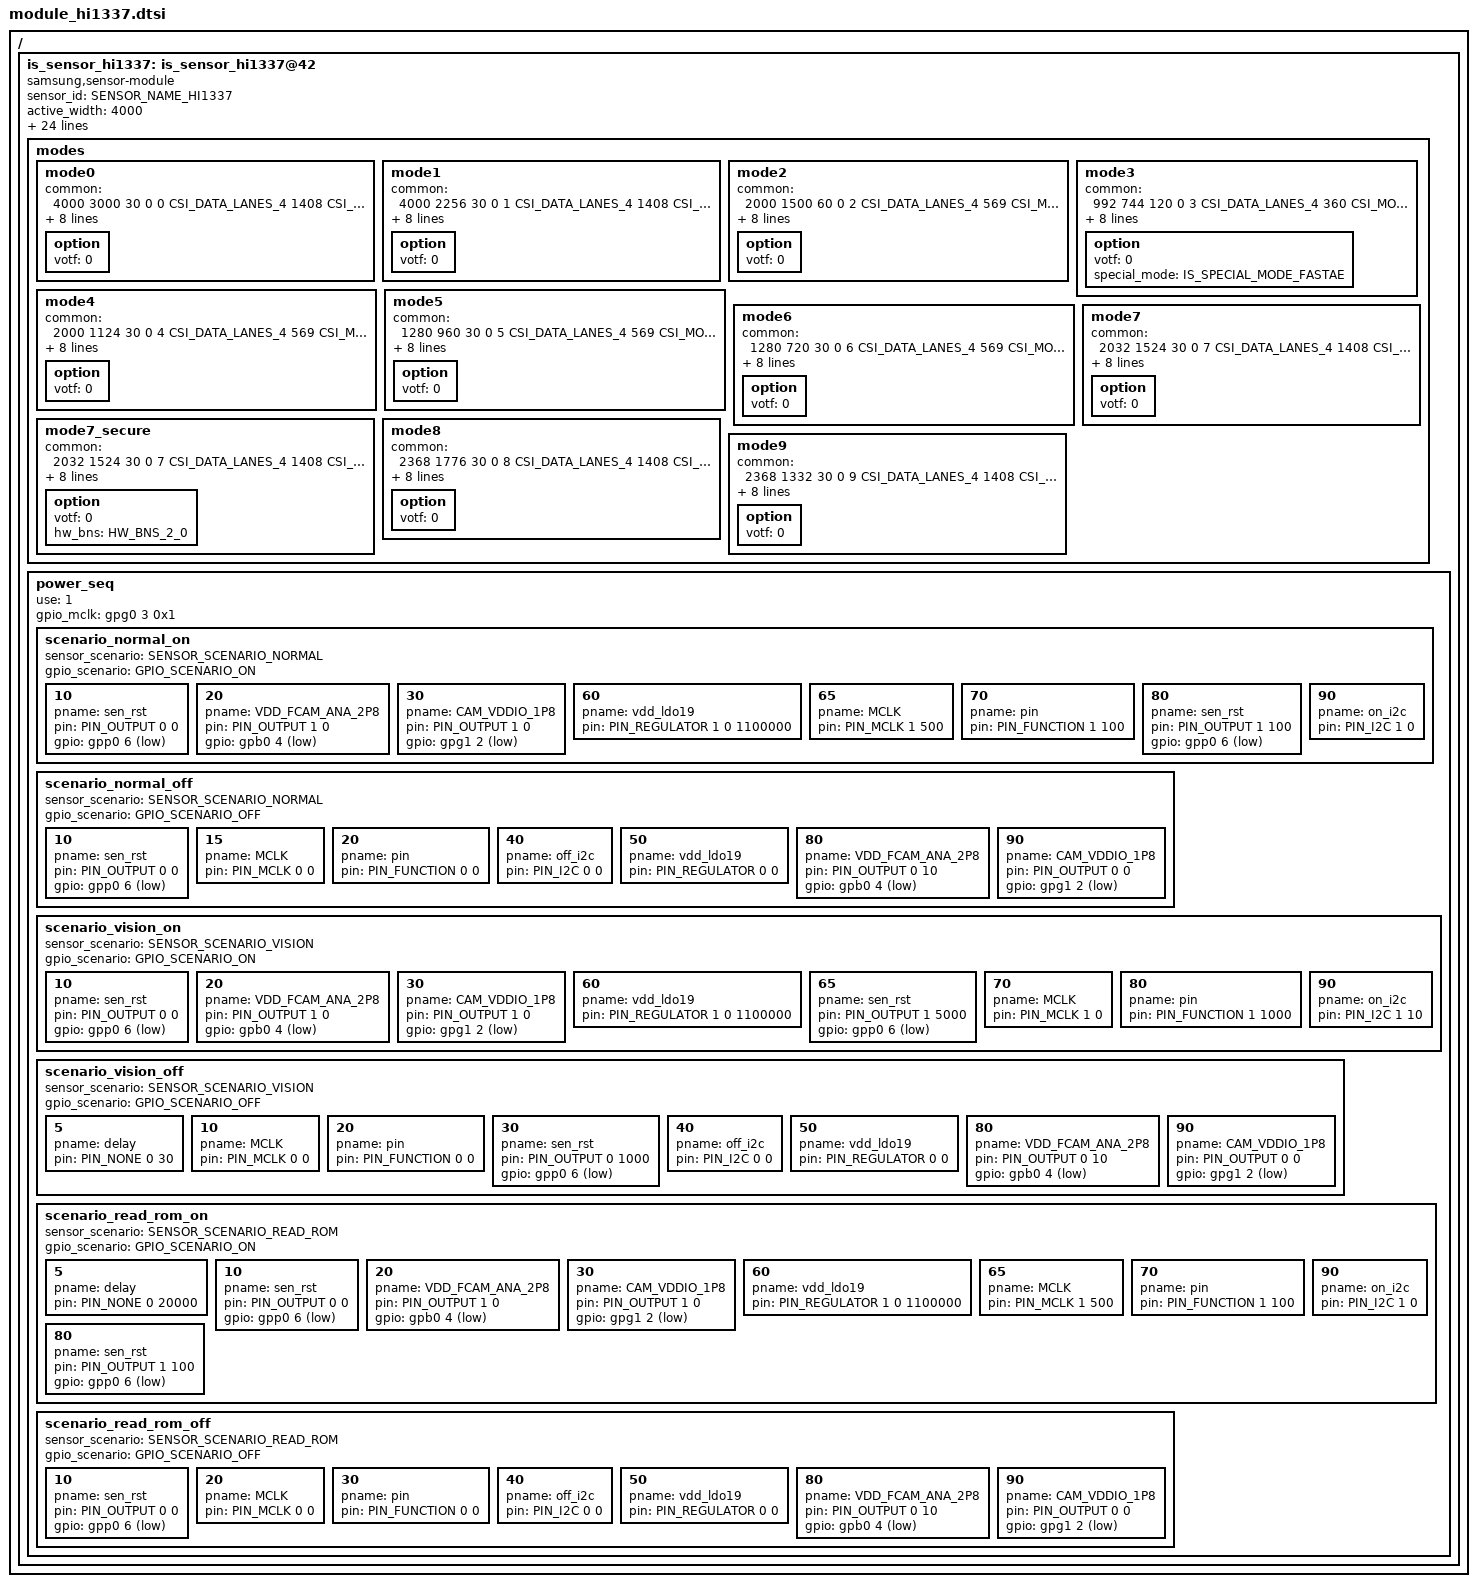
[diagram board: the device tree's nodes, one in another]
/*
 * SAMSUNG EXYNOSxxxx board camera device tree source
 *
 * Copyright (c) 2024 Samsung Electronics Co., Ltd.
 *		http://www.samsung.com
 *
 * This program is free software; you can redistribute it and/or modify
 * it under the terms of the GNU General Public License version 2 as
 * published by the Free Software Foundation.
 */

#include <dt-bindings/camera/exynos_is_dt.h>

/ {
	fragment@camera {
		target-path = "/";
		__overlay__ {
			is_sensor_hi1337: is_sensor_hi1337@42 {
				compatible = "samsung,sensor-module";

				/* common */
				sensor_id = <SENSOR_NAME_HI1337>;
				active_width = <4000>;
				active_height = <3000>;
				margin_left = <0>;
				margin_right = <0>;
				margin_top = <0>;
				margin_bottom = <0>;
				max_framerate = <120>;
				bitwidth = <10>;
				use_retention_mode = <SENSOR_RETENTION_UNSUPPORTED>;
				sensor_maker = "HYNIX";
				sensor_name = "HI1337";
				setfile_name = "setfile_hi1337.bin";
				pinning_setfile;
				//preload_setfile;

				status = "okay";

				/* board */
				pinctrl-names = "pin0", "pin1", "release";
				pinctrl-0 = <&sensor_mclk2_out>;
				pinctrl-1 = <&sensor_mclk2_fn>;
				pinctrl-2 = <>;

				position = <1>; /* Rear:0. Front:1, Tele:2 */
				id = <1>; /* is_sensor id */
				mclk_ch = <2>;
				mclk_freq = <19200>;
				sensor_i2c_ch = <4>; /* SENSOR_CONTROL_I2C1 */

				/* vendor */
				rom_id = <1>;
				rom_cal_index = <0>;
				rom_type = <3>; /* ROM_TYPE_OTPROM */
#if 0
				vc_extra {
					/* ex) statX = <stat_type, sensor_mode, max_width, max_height, max_element> */
					/* VC_BUF_DATA_TYPE_SENSOR_STAT1 */
					stat0 = </*VC_STAT_TYPE_TAIL_FOR_3HDR_IMX_2_STAT0*/ 602    /*VC_SENSOR_MODE_3HDR_IMX_2*/ 602 4080 2 1>;
					/* VC_BUF_DATA_TYPE_GENERAL_STAT1 */
					stat1 = </* not available */>;
					/* VC_BUF_DATA_TYPE_SENSOR_STAT2 */
					stat2 = </*VC_STAT_TYPE_TAIL_FOR_3HDR_IMX_2_STAT1*/ 603    /*VC_SENSOR_MODE_3HDR_IMX_2*/ 602 4080 3 1>;
					/* VC_BUF_DATA_TYPE_GENERAL_STAT2 */
					stat3 = </* not available */>;
				};
#endif

				/* sensor modes */
				modes {
						/* common = <width, height, fps, settle, mode, lane, speed, interleave, lrte, pd_mode> */
						/* vcX = <map, hwformat, width, height, hwformat, type, width, height> */

						/* 0 : 4000x3000_30FPS */
						mode0 {
								common = <4000 3000 30 0 0 CSI_DATA_LANES_4 1408 CSI_MODE_VC_ONLY LRTE_DISABLE PD_NONE EX_NONE>;
								vc0 = </* in */ 0 HW_FORMAT_RAW10 DATA_IMG 4000 3000 /* out */ HW_FORMAT_RAW10 VC_NOTHING 4000 3000>;
								vc1 = </* in */ 1 HW_FORMAT_UNKNOWN DATA_NONE 0 0 /* out */ HW_FORMAT_UNKNOWN VC_NOTHING 0 0>;
								vc2 = </* in */ 2 HW_FORMAT_UNKNOWN DATA_NONE 0 0 /* out */ HW_FORMAT_UNKNOWN VC_NOTHING 0 0>;
								vc3 = </* in */ 3 HW_FORMAT_UNKNOWN DATA_NONE 0 0 /* out */ HW_FORMAT_UNKNOWN VC_NOTHING 0 0>;
								option { votf = <0>; };
						};

						/* 1 : 4000x2256_30FPS */
						mode1 {
								common = <4000 2256 30 0 1 CSI_DATA_LANES_4 1408 CSI_MODE_VC_ONLY LRTE_DISABLE PD_NONE EX_NONE>;
								vc0 = </* in */ 0 HW_FORMAT_RAW10 DATA_IMG 4000 2256     /* out */ HW_FORMAT_RAW10 VC_NOTHING 4000 2256>;
								vc1 = </* in */ 1 HW_FORMAT_UNKNOWN DATA_NONE 0 0 /* out */ HW_FORMAT_UNKNOWN VC_NOTHING 0 0>;
								vc2 = </* in */ 2 HW_FORMAT_UNKNOWN DATA_NONE 0 0 /* out */ HW_FORMAT_UNKNOWN VC_NOTHING 0 0>;
								vc3 = </* in */ 3 HW_FORMAT_UNKNOWN DATA_NONE 0 0 /* out */ HW_FORMAT_UNKNOWN VC_NOTHING 0 0>;
								option { votf = <0>; };
						};

						/* 2 : 2000x1500_60fps */
						mode2 {
								common = <2000 1500 60 0 2 CSI_DATA_LANES_4 569 CSI_MODE_VC_ONLY LRTE_DISABLE PD_NONE EX_NONE>;
								vc0 = </* in */ 0 HW_FORMAT_RAW10 DATA_IMG 2000 1500 /* out */ HW_FORMAT_RAW10 VC_NOTHING 2000 1500>;
								vc1 = </* in */ 1 HW_FORMAT_UNKNOWN DATA_NONE 0 0 /* out */ HW_FORMAT_UNKNOWN VC_NOTHING 0 0>;
								vc2 = </* in */ 2 HW_FORMAT_UNKNOWN DATA_NONE 0 0 /* out */ HW_FORMAT_UNKNOWN VC_NOTHING 0 0>;
								vc3 = </* in */ 3 HW_FORMAT_UNKNOWN DATA_NONE 0 0 /* out */ HW_FORMAT_UNKNOWN VC_NOTHING 0 0>;
								option { votf = <0>; };
						};

						/* 3 : 992x744_120fps */
						mode3 {
								common = <992 744 120 0 3 CSI_DATA_LANES_4 360 CSI_MODE_VC_ONLY LRTE_DISABLE PD_NONE EX_NONE>;
								vc0 = </* in */ 0 HW_FORMAT_RAW10 DATA_IMG 992 744     /* out */ HW_FORMAT_RAW10 VC_NOTHING 992 744>;
								vc1 = </* in */ 1 HW_FORMAT_UNKNOWN DATA_NONE 0 0 /* out */ HW_FORMAT_UNKNOWN VC_NOTHING 0 0>;
								vc2 = </* in */ 2 HW_FORMAT_UNKNOWN DATA_NONE 0 0 /* out */ HW_FORMAT_UNKNOWN VC_NOTHING 0 0>;
								vc3 = </* in */ 3 HW_FORMAT_UNKNOWN DATA_NONE 0 0 /* out */ HW_FORMAT_UNKNOWN VC_NOTHING 0 0>;
								option { votf = <0>; special_mode = <IS_SPECIAL_MODE_FASTAE>; };
						};

						/* 4 : 2000x1124_30fps */
						mode4 {
								common = <2000 1124 30 0 4 CSI_DATA_LANES_4 569 CSI_MODE_VC_ONLY LRTE_DISABLE PD_NONE EX_NONE>;
								vc0 = </* in */ 0 HW_FORMAT_RAW10 DATA_IMG 2000 1124 /* out */ HW_FORMAT_RAW10 VC_NOTHING 2000 1124>;
								vc1 = </* in */ 1 HW_FORMAT_UNKNOWN DATA_NONE 0 0 /* out */ HW_FORMAT_UNKNOWN VC_NOTHING 0 0>;
								vc2 = </* in */ 2 HW_FORMAT_UNKNOWN DATA_NONE 0 0 /* out */ HW_FORMAT_UNKNOWN VC_NOTHING 0 0>;
								vc3 = </* in */ 3 HW_FORMAT_UNKNOWN DATA_NONE 0 0 /* out */ HW_FORMAT_UNKNOWN VC_NOTHING 0 0>;
								option { votf = <0>; };
						};

						/* 5 : 1280x960_30fps */
						mode5 {
								common = <1280 960 30 0 5 CSI_DATA_LANES_4 569 CSI_MODE_VC_ONLY LRTE_DISABLE PD_NONE EX_NONE>;
								vc0 = </* in */ 0 HW_FORMAT_RAW10 DATA_IMG 1280 960     /* out */ HW_FORMAT_RAW10 VC_NOTHING 1280 960>;
								vc1 = </* in */ 1 HW_FORMAT_UNKNOWN DATA_NONE 0 0 /* out */ HW_FORMAT_UNKNOWN VC_NOTHING 0 0>;
								vc2 = </* in */ 2 HW_FORMAT_UNKNOWN DATA_NONE 0 0 /* out */ HW_FORMAT_UNKNOWN VC_NOTHING 0 0>;
								vc3 = </* in */ 3 HW_FORMAT_UNKNOWN DATA_NONE 0 0 /* out */ HW_FORMAT_UNKNOWN VC_NOTHING 0 0>;
								option { votf = <0>; };
						};

						/* 6 : 1280x720_30fps */
						mode6 {
								common = <1280 720 30 0 6 CSI_DATA_LANES_4 569 CSI_MODE_VC_ONLY LRTE_DISABLE PD_NONE EX_NONE>;
								vc0 = </* in */ 0 HW_FORMAT_RAW10 DATA_IMG 1280 720     /* out */ HW_FORMAT_RAW10 VC_NOTHING 1280 720>;
								vc1 = </* in */ 1 HW_FORMAT_UNKNOWN DATA_NONE 0 0 /* out */ HW_FORMAT_UNKNOWN VC_NOTHING 0 0>;
								vc2 = </* in */ 2 HW_FORMAT_UNKNOWN DATA_NONE 0 0 /* out */ HW_FORMAT_UNKNOWN VC_NOTHING 0 0>;
								vc3 = </* in */ 3 HW_FORMAT_UNKNOWN DATA_NONE 0 0 /* out */ HW_FORMAT_UNKNOWN VC_NOTHING 0 0>;
								option { votf = <0>; };
						};

						/* 7 : 2032x1524_30fps */
						mode7 {
								common = <2032 1524 30 0 7 CSI_DATA_LANES_4 1408 CSI_MODE_VC_ONLY LRTE_DISABLE PD_NONE EX_NONE>;
								vc0 = </* in */ 0 HW_FORMAT_RAW10 DATA_IMG 2032 1524     /* out */ HW_FORMAT_RAW10 VC_NOTHING 2032 1524>;
								vc1 = </* in */ 1 HW_FORMAT_UNKNOWN DATA_NONE 0 0 /* out */ HW_FORMAT_UNKNOWN VC_NOTHING 0 0>;
								vc2 = </* in */ 2 HW_FORMAT_UNKNOWN DATA_NONE 0 0 /* out */ HW_FORMAT_UNKNOWN VC_NOTHING 0 0>;
								vc3 = </* in */ 3 HW_FORMAT_UNKNOWN DATA_NONE 0 0 /* out */ HW_FORMAT_UNKNOWN VC_NOTHING 0 0>;
								option { votf = <0>; };
						};

						mode7_secure {
								common = <2032 1524 30 0 7 CSI_DATA_LANES_4 1408 CSI_MODE_VC_ONLY LRTE_DISABLE PD_NONE EX_PDAF_OFF>;
								vc0 = </* in */ 0 HW_FORMAT_RAW10 DATA_IMG 2032 1524 /* out */ HW_FORMAT_RAW10 VC_NOTHING 1016 762>;
								vc1 = </* in */ 1 HW_FORMAT_UNKNOWN DATA_NONE 0 0 /* out */ HW_FORMAT_UNKNOWN VC_NOTHING 0 0>;
								vc2 = </* in */ 2 HW_FORMAT_UNKNOWN DATA_NONE 0 0 /* out */ HW_FORMAT_UNKNOWN VC_NOTHING 0 0>;
								vc3 = </* in */ 3 HW_FORMAT_UNKNOWN DATA_NONE 0 0 /* out */ HW_FORMAT_UNKNOWN VC_NOTHING 0 0>;
								option { votf = <0>; hw_bns = <HW_BNS_2_0>; };
						};

						mode8 {
								common = <2368 1776 30 0 8 CSI_DATA_LANES_4 1408 CSI_MODE_VC_ONLY LRTE_DISABLE PD_NONE EX_NONE>;
								vc0 = </* in */ 0 HW_FORMAT_RAW10 DATA_IMG 2368 1776     /* out */ HW_FORMAT_RAW10 VC_NOTHING 2368 1776>;
								vc1 = </* in */ 1 HW_FORMAT_UNKNOWN DATA_NONE 0 0 /* out */ HW_FORMAT_UNKNOWN VC_NOTHING 0 0>;
								vc2 = </* in */ 2 HW_FORMAT_UNKNOWN DATA_NONE 0 0 /* out */ HW_FORMAT_UNKNOWN VC_NOTHING 0 0>;
								vc3 = </* in */ 3 HW_FORMAT_UNKNOWN DATA_NONE 0 0 /* out */ HW_FORMAT_UNKNOWN VC_NOTHING 0 0>;
								option { votf = <0>; };
						};

						mode9 {
								common = <2368 1332 30 0 9 CSI_DATA_LANES_4 1408 CSI_MODE_VC_ONLY LRTE_DISABLE PD_NONE EX_NONE>;
								vc0 = </* in */ 0 HW_FORMAT_RAW10 DATA_IMG 2368 1332    /* out */ HW_FORMAT_RAW10 VC_NOTHING 2368 1332>;
								vc1 = </* in */ 1 HW_FORMAT_UNKNOWN DATA_NONE 0 0 /* out */ HW_FORMAT_UNKNOWN VC_NOTHING 0 0>;
								vc2 = </* in */ 2 HW_FORMAT_UNKNOWN DATA_NONE 0 0 /* out */ HW_FORMAT_UNKNOWN VC_NOTHING 0 0>;
								vc3 = </* in */ 3 HW_FORMAT_UNKNOWN DATA_NONE 0 0 /* out */ HW_FORMAT_UNKNOWN VC_NOTHING 0 0>;
								option { votf = <0>; };
						};

				};

				power_seq {
					use = <1>;
					gpio_mclk = <&gpg0 3 0x1>;
					scenario_normal_on {
						sensor_scenario = <SENSOR_SCENARIO_NORMAL>;
						gpio_scenario = <GPIO_SCENARIO_ON>;

						/* A start node number should be over the 10 for reserved number 0~9. */
						/* pname = "name"; pin = <act value delay voltage>; gpio = <gpx# # 0x1>; */
						10 { pname = "sen_rst"; pin = <PIN_OUTPUT 0 0>; gpio = <&gpp0 6 0x1>; };
						20 { pname = "VDD_FCAM_ANA_2P8"; pin = <PIN_OUTPUT 1 0>; gpio = <&gpb0 4 0x1>; };
						30 { pname = "CAM_VDDIO_1P8"; pin = <PIN_OUTPUT 1 0>; gpio = <&gpg1 2 0x1>; };
						60 { pname = "vdd_ldo19"; pin = <PIN_REGULATOR 1 0 1100000>; };
						65 { pname = "MCLK"; pin = <PIN_MCLK 1 500>; };
						70 { pname = "pin"; pin = <PIN_FUNCTION 1 100>; };
						80 { pname = "sen_rst"; pin = <PIN_OUTPUT 1 100>; gpio = <&gpp0 6 0x1>; };
						90 { pname = "on_i2c"; pin = <PIN_I2C 1 0>; };
					};

					scenario_normal_off {
						sensor_scenario = <SENSOR_SCENARIO_NORMAL>;
						gpio_scenario = <GPIO_SCENARIO_OFF>;

						/* A start node number should be over the 10 for reserved number 0~9. */
						/* pname = "name"; pin = <act value delay voltage>; gpio = <gpx# # 0x1>; */
						10 { pname = "sen_rst"; pin = <PIN_OUTPUT 0 0>; gpio = <&gpp0 6 0x1>; };
						15 { pname = "MCLK"; pin = <PIN_MCLK 0 0>; };
						20 { pname = "pin"; pin = <PIN_FUNCTION 0 0>; };
						40 { pname = "off_i2c"; pin = <PIN_I2C 0 0>; };
						50 { pname = "vdd_ldo19"; pin = <PIN_REGULATOR 0 0>; };
						80 { pname = "VDD_FCAM_ANA_2P8"; pin = <PIN_OUTPUT 0 10>; gpio = <&gpb0 4 0x1>; };
						90 { pname = "CAM_VDDIO_1P8"; pin = <PIN_OUTPUT 0 0>; gpio = <&gpg1 2 0x1>; };
					};

					scenario_vision_on {
						sensor_scenario = <SENSOR_SCENARIO_VISION>;
						gpio_scenario = <GPIO_SCENARIO_ON>;

						/* A start node number should be over the 10 for reserved number 0~9. */
						/* pname = "name"; pin = <act value delay voltage>; gpio = <gpx# # 0x1>; */
						10 { pname = "sen_rst"; pin = <PIN_OUTPUT 0 0>; gpio = <&gpp0 6 0x1>; };
						20 { pname = "VDD_FCAM_ANA_2P8"; pin = <PIN_OUTPUT 1 0>; gpio = <&gpb0 4 0x1>; };
						30 { pname = "CAM_VDDIO_1P8"; pin = <PIN_OUTPUT 1 0>; gpio = <&gpg1 2 0x1>; };
						60 { pname = "vdd_ldo19"; pin = <PIN_REGULATOR 1 0 1100000>; };
						65 { pname = "sen_rst"; pin = <PIN_OUTPUT 1 5000>; gpio = <&gpp0 6 0x1>; };
						70 { pname = "MCLK"; pin = <PIN_MCLK 1 0>; };
						80 { pname = "pin"; pin = <PIN_FUNCTION 1 1000>; };
						90 { pname = "on_i2c"; pin = <PIN_I2C 1 10>; };
					};

					scenario_vision_off {
						sensor_scenario = <SENSOR_SCENARIO_VISION>;
						gpio_scenario = <GPIO_SCENARIO_OFF>;

						/* A start node number should be over the 10 for reserved number 0~9. */
						/* pname = "name"; pin = <act value delay voltage>; gpio = <gpx# # 0x1>; */
						5 { pname = "delay"; pin = <PIN_NONE 0 30>; };
						10 { pname = "MCLK"; pin = <PIN_MCLK 0 0>; };
						20 { pname = "pin"; pin = <PIN_FUNCTION 0 0>; };
						30 { pname = "sen_rst"; pin = <PIN_OUTPUT 0 1000>; gpio = <&gpp0 6 0x1>; };
						40 { pname = "off_i2c"; pin = <PIN_I2C 0 0>; };
						50 { pname = "vdd_ldo19"; pin = <PIN_REGULATOR 0 0>; };
						80 { pname = "VDD_FCAM_ANA_2P8"; pin = <PIN_OUTPUT 0 10>; gpio = <&gpb0 4 0x1>; };
						90 { pname = "CAM_VDDIO_1P8"; pin = <PIN_OUTPUT 0 0>; gpio = <&gpg1 2 0x1>; };
					};

					scenario_read_rom_on {
						sensor_scenario = <SENSOR_SCENARIO_READ_ROM>;
						gpio_scenario = <GPIO_SCENARIO_ON>;

						/* A start node number should be over the 10 for reserved number 0~9. */
						/* pname = "name"; pin = <act value delay voltage>; gpio = <gpx# # 0x1>; */
						5 { pname = "delay"; pin = <PIN_NONE 0 20000>; };
						10 { pname = "sen_rst"; pin = <PIN_OUTPUT 0 0>; gpio = <&gpp0 6 0x1>; };
						20 { pname = "VDD_FCAM_ANA_2P8"; pin = <PIN_OUTPUT 1 0>; gpio = <&gpb0 4 0x1>; };
						30 { pname = "CAM_VDDIO_1P8"; pin = <PIN_OUTPUT 1 0>; gpio = <&gpg1 2 0x1>; };
						60 { pname = "vdd_ldo19"; pin = <PIN_REGULATOR 1 0 1100000>; };
						65 { pname = "MCLK"; pin = <PIN_MCLK 1 500>; };
						70 { pname = "pin"; pin = <PIN_FUNCTION 1 100>; };
						80 { pname = "sen_rst"; pin = <PIN_OUTPUT 1 100>; gpio = <&gpp0 6 0x1>; };
						90 { pname = "on_i2c"; pin = <PIN_I2C 1 0>; };
					};
					scenario_read_rom_off {
						sensor_scenario = <SENSOR_SCENARIO_READ_ROM>;
						gpio_scenario = <GPIO_SCENARIO_OFF>;

						/* A start node number should be over the 10 for reserved number 0~9. */
						/* pname = "name"; pin = <act value delay voltage>; gpio = <gpx# # 0x1>; */
						10 { pname = "sen_rst"; pin = <PIN_OUTPUT 0 0>; gpio = <&gpp0 6 0x1>; };
						20 { pname = "MCLK"; pin = <PIN_MCLK 0 0>; };
						30 { pname = "pin"; pin = <PIN_FUNCTION 0 0>; };
						40 { pname = "off_i2c"; pin = <PIN_I2C 0 0>; };
						50 { pname = "vdd_ldo19"; pin = <PIN_REGULATOR 0 0>; };
						80 { pname = "VDD_FCAM_ANA_2P8"; pin = <PIN_OUTPUT 0 10>; gpio = <&gpb0 4 0x1>; };
						90 { pname = "CAM_VDDIO_1P8"; pin = <PIN_OUTPUT 0 0>; gpio = <&gpg1 2 0x1>; };
					};
				};
			};
		}; /* end of __overlay__ */
	}; /* end of fragment */
}; /* end of root */
